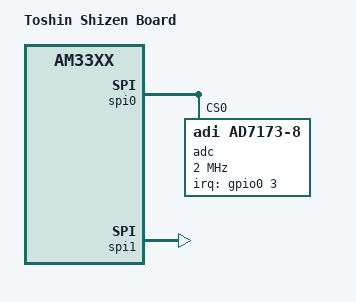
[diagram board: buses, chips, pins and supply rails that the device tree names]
// SPDX-License-Identifier: GPL-2.0-only
/*
 * Copyright (C) 2012 Texas Instruments Incorporated - https://www.ti.com/
 */
/dts-v1/;

#include "am33xx.dtsi"
#include "am335x-bone-common.dtsi"
#include "am335x-boneblack-common.dtsi"

/ {
	model = "Toshin Shizen Board";
	compatible = "ti,am335x-bone-black", "ti,am335x-bone", "ti,am33xx";
};

&spi0 {
    status = "okay";
    pinctrl-names = "default";
    pinctrl-0 = <&spi0_adc_pins_default>;
    // #address-cells = <1>;
    // #size-cells = <0>;

    adc@0 {
        compatible = "adi,ad7173-8";
        reg = <0>;
        interrupts = <3 IRQ_TYPE_EDGE_FALLING>;
        interrupt-parent = <&gpio0>;
        spi-max-frequency = <2000000>;
        adi,channels {
            #address-cells = <2>;
            #size-cells = <0>;

            channel@0,1 {
                reg = <0 1>;
                // adi,bipolar;
            };
            channel@2,3 {
                reg = <15 8>;
                // adi,bipolar;
            };
            // channel@2,3 {
            //     reg = <2 3>;
            //     adi,bipolar;
            //     // diff-channels = <2 3>;
            // };
        };
    };
};
&spi1  {
    status = "okay";
    pinctrl-names = "default";
    pinctrl-0 = <&spi1_wifi_pins_default>;
    // ti,pindir-d0-out-d1-in;
	// spidev@0 {
    //             compatible = "spidev";
    //             reg = <0>; // CS #0 
    //             spi-max-frequency = <10000000>; //10Mhz
    //     };    

};
